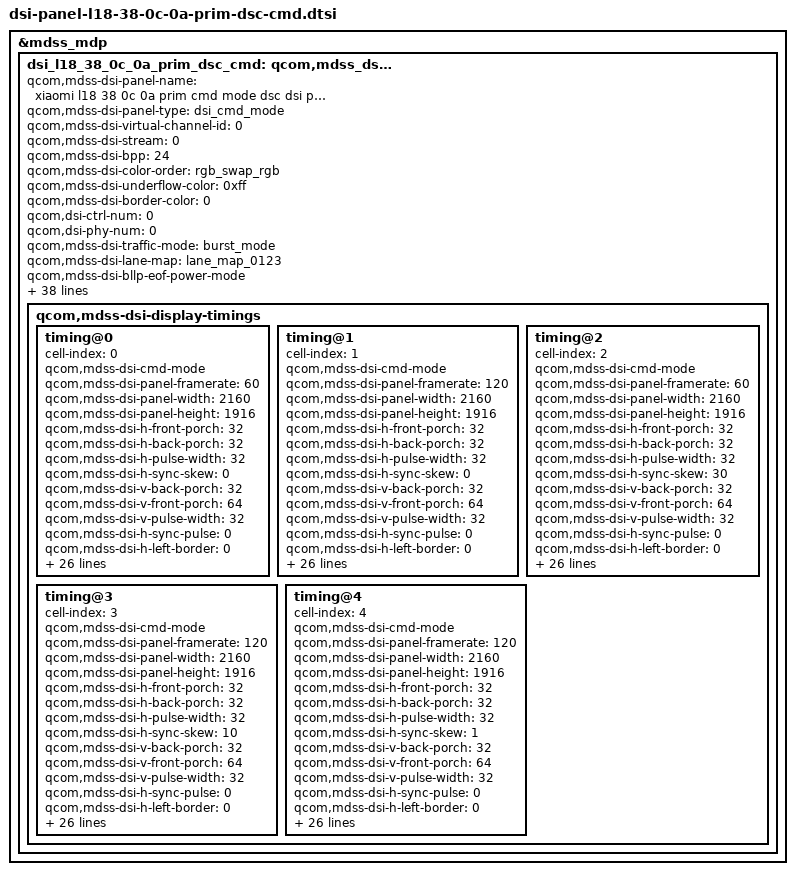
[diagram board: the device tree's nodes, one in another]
&mdss_mdp {
	dsi_l18_38_0c_0a_prim_dsc_cmd: qcom,mdss_dsi_l18_38_0c_0a_prim_dsc_cmd {
		qcom,mdss-dsi-panel-name = "xiaomi l18 38 0c 0a prim cmd mode dsc dsi panel";
		qcom,mdss-dsi-panel-type = "dsi_cmd_mode";
		qcom,mdss-dsi-virtual-channel-id = <0>;
		qcom,mdss-dsi-stream = <0>;
		qcom,mdss-dsi-bpp = <24>;
		qcom,mdss-dsi-color-order = "rgb_swap_rgb";
		qcom,mdss-dsi-underflow-color = <0xff>;
		qcom,mdss-dsi-border-color = <0>;
		qcom,dsi-ctrl-num = <0>;
		qcom,dsi-phy-num = <0>;

		qcom,mdss-dsi-traffic-mode = "burst_mode";
		qcom,mdss-dsi-lane-map = "lane_map_0123";
		qcom,mdss-dsi-bllp-eof-power-mode;
		qcom,mdss-dsi-bllp-power-mode;
		qcom,mdss-dsi-lane-0-state;
		qcom,mdss-dsi-lane-1-state;
		qcom,mdss-dsi-lane-2-state;
		qcom,mdss-dsi-lane-3-state;
		qcom,mdss-dsi-dma-trigger = "trigger_sw";
		qcom,mdss-dsi-mdp-trigger = "none";
		qcom,mdss-dsi-reset-sequence = <0 1>, <1 10>;
		qcom,mdss-pan-physical-width-dimension = <1350>;
		qcom,mdss-pan-physical-height-dimension = <1521>;
		qcom,mdss-dsi-te-pin-select = <1>;
		qcom,mdss-dsi-wr-mem-start = <0x2c>;
		qcom,mdss-dsi-wr-mem-continue = <0x3c>;
		qcom,mdss-dsi-te-dcs-command = <1>;
		qcom,mdss-dsi-te-check-enable;
		qcom,mdss-dsi-te-using-te-pin;
		qcom,mdss-dsi-tx-eot-append;
		qcom,mdss-dsi-lp11-init;

		qcom,mdss-dsi-panel-mode-switch;

		qcom,mdss-dsi-bl-inverted-dbv;
		qcom,bl-update-flag = "delay_until_first_frame";

		qcom,mdss-dsi-dma-schedule-line = <1>;
		qcom,mdss-dsi-dma-schedule-window = <10>;

		qcom,mdss-dsi-panel-hdr-enabled;
		qcom,mdss-dsi-panel-hdr-color-primaries = <14500 15500 32000
			17000 15500 30000 8000 3000>;
		qcom,mdss-dsi-panel-peak-brightness = <4200000>;
		qcom,mdss-dsi-panel-blackness-level = <3230>;

		qcom,mdss-dsi-display-timings {
			/* 60HZ */
			timing@0{
				#include "dsi-panel-l18-38-0c-0a-prim-dsc-cmd-common.dtsi"
				cell-index = <0>;
				qcom,mdss-dsi-cmd-mode;
				qcom,mdss-dsi-panel-framerate = <60>;
				qcom,mdss-dsi-panel-width = <2160>;
				qcom,mdss-dsi-panel-height = <1916>;
				qcom,mdss-dsi-h-front-porch = <32>;
				qcom,mdss-dsi-h-back-porch = <32>;
				qcom,mdss-dsi-h-pulse-width = <32>;
				qcom,mdss-dsi-h-sync-skew = <0>;
				qcom,mdss-dsi-v-back-porch = <32>;
				qcom,mdss-dsi-v-front-porch = <64>;
				qcom,mdss-dsi-v-pulse-width = <32>;
				qcom,mdss-dsi-h-sync-pulse = <0>;
				qcom,mdss-dsi-h-left-border = <0>;
				qcom,mdss-dsi-h-right-border = <0>;
				qcom,mdss-dsi-v-top-border = <0>;
				qcom,mdss-dsi-v-bottom-border = <0>;
				qcom,mdss-dsi-panel-clockrate = <1200000000>;
				qcom,mdss-dsi-panel-jitter = <0x5 0x1>;
				qcom,mdss-mdp-transfer-time-us = <7300>;
				qcom,mdss-dsi-on-command = [
					/* DSC Setting */
					39 00 00 00 00 00 5A 9E 11 00 00 89 30
					80 07 7C 08 70 01 DF 04 38 04 38 02
					00 03 1C 00 20 3D F1 00 0F 00 0C 00
					34 00 1C 18 00 10 F0 03 0C 20 00 06
					0B 0B 33 0E 1C 2A 38 46 54 62 69 70
					77 79 7B 7D 7E 01 02 01 00 09 40 09
					BE 19 FC 19 FA 19 F8 1A 38 1A 78 1A
					B6 2A F6 2B 34 2B 74 3B 74 6B F4 00
					/* Compression Enable */
					15 00 00 00 00 00 02 9D 01
					/* Sleep Out */
					05 00 00 00 78 00 02 11 00
					/* Common Setting */
					/* TE(Vsync) On */
					15 00 00 00 00 00 02 35 00
					/* CASET/PASET Setting 2160*1916 */
					39 00 00 40 00 00 05 2A 00 00 08 6F
					39 00 00 00 00 00 05 2B 00 00 07 7B
					/* TSP SYNC ENABLE */
					39 00 00 40 00 00 03 F0 5A 5A
					39 00 00 40 00 00 03 B0 09 B9
					39 00 00 40 00 00 04 B9 11 00 03
					39 00 00 00 00 00 03 F0 A5 A5
					/* Frequency Select 60.5Hz */
					39 00 00 40 00 00 03 F0 5A 5A
					39 00 00 40 00 00 03 60 08 00
					39 00 00 40 00 00 03 B0 03 F2
					15 00 00 40 00 00 02 F2 70
					15 00 00 40 00 00 02 B9 11
					15 00 00 40 00 00 02 F7 0F
					39 00 00 00 00 00 03 F0 A5 A5
					/* HOP Mode 60.5HZ */
					39 00 00 40 00 00 03 F0 5A 5A
					39 00 00 40 00 00 08 BD 01 00 00 80 00 01 C0
					39 00 00 40 00 00 03 60 08 01
					15 00 00 40 00 00 02 F7 0F
					39 00 00 00 00 00 03 F0 A5 A5
					/* Dimming Setting*/
					39 00 00 40 00 00 03 F0 5A 5A
					39 00 00 40 00 00 03 B0 02 B5
					39 00 00 40 00 00 02 B5 0F
					39 00 00 40 00 00 02 53 28
					39 00 00 40 00 00 03 51 00 00
					39 00 00 40 00 00 02 F7 0F
					39 00 00 00 00 00 03 F0 A5 A5
					/* Signal DC value setting after sleep out */
					39 00 00 40 00 00 03 F0 5A 5A
					39 00 00 40 00 00 03 B0 0A CB
					15 00 00 40 00 00 02 CB 0F
					39 00 00 40 00 00 03 B0 9D 64
					15 00 00 40 00 00 02 64 09
					15 00 00 40 00 00 02 F7 0F
					39 00 00 00 00 00 03 F0 A5 A5
					/* 2D SPR CTRL*/
					39 00 00 40 00 00 03 F0 5A 5A
					39 00 00 40 00 00 03 B0 64 B1
					39 00 00 40 00 00 02 B1 B8
					39 00 00 40 00 00 08 64 00 08 D8 D8 FF FF 40
					39 00 00 00 00 00 03 F0 A5 A5
					/* ERR Flag Setting ,ESD En*/
					39 00 00 40 00 00 03 F0 5A 5A
					39 00 00 40 00 00 03 B0 2A F4
					39 00 00 40 00 00 02 F4 3F
					39 00 00 40 00 00 04 ED 43 49 62
					39 00 00 00 00 00 03 F0 A5 A5
					/*flat dimming*/
					39 00 00 40 00 00 03 F0 5A 5A
					39 00 00 40 00 00 03 B0 C5 93
					15 00 00 40 00 00 02 93 87
					39 00 00 00 00 00 03 F0 A5 A5
					/*round corner improve*/
					39 00 00 40 00 00 03 F0 5A 5A
					39 00 00 40 00 00 03 B0 29 F2
					15 00 00 40 00 00 02 F2 04
					39 00 00 00 00 00 03 F0 A5 A5
					/* Display On */
					05 00 00 00 00 00 02 29 00
				];
				qcom,mdss-dsi-on-command-state = "dsi_lp_mode";
				qcom,mdss-dsi-off-command = [
					05 00 00 00 00 00 02 28 00
					05 00 00 00 0A 00 02 10 00
					39 00 00 40 00 00 03 F0 5A 5A
					39 00 00 40 00 00 03 B0 0A CB
					15 00 00 40 00 00 02 CB 4F
					15 00 00 40 00 00 02 F7 0F
					39 00 00 00 78 00 03 F0 A5 A5
				];
				qcom,mdss-dsi-off-command-state = "dsi_lp_mode";

				qcom,mdss-dsi-timing-switch-command = [
					39 00 00 40 00 00 03 F0 5A 5A
					39 00 00 40 00 00 03 60 08 00
					39 00 00 40 00 00 03 B0 03 F2
					/* Fix Te On */
					39 00 00 40 00 00 02 F2 70
					39 00 00 40 00 00 02 B9 11
					/* HOP Mode */
					39 00 00 40 00 00 08 BD 01 00 00 80 00 01 C0
					/* Frequency Select 60.5Hz */
					39 00 00 40 00 00 03 60 08 01
					39 00 00 00 00 00 02 F7 0F
				];
				qcom,mdss-dsi-timing-switch-command-state = "dsi_hs_mode";

				qcom,mdss-dsi-nolp-command = [
					39 00 00 40 00 00 03 F0 5A 5A
					39 00 00 40 00 00 03 B0 02 B5
					15 00 00 40 00 00 02 B5 0F
					15 00 00 40 00 00 02 53 20
					15 00 00 40 00 00 02 F7 0F
					/* Frequency Select 60.5Hz */
					39 00 00 40 00 00 03 60 08 00
					39 00 00 40 00 00 03 B0 03 F2
					15 00 00 40 00 00 02 F2 70
					15 00 00 40 00 00 02 B9 11
					15 00 00 40 00 00 02 F7 0F
					39 00 00 00 00 00 03 F0 A5 A5
				];
				qcom,mdss-dsi-nolp-command-state = "dsi_lp_mode";

				qcom,compression-mode = "dsc";
				qcom,mdss-dsc-slice-height = <479>;
				qcom,mdss-dsc-slice-width = <1080>;
				qcom,mdss-dsc-slice-per-pkt = <2>;
				qcom,mdss-dsc-bit-per-component = <8>;
				qcom,mdss-dsc-bit-per-pixel = <8>;
				qcom,mdss-dsc-block-prediction-enable;
			};

			/* 120HZ */
			timing@1{
				#include "dsi-panel-l18-38-0c-0a-prim-dsc-cmd-common.dtsi"
				cell-index = <1>;
				qcom,mdss-dsi-cmd-mode;
				qcom,mdss-dsi-panel-framerate = <120>;
				qcom,mdss-dsi-panel-width = <2160>;
				qcom,mdss-dsi-panel-height = <1916>;
				qcom,mdss-dsi-h-front-porch = <32>;
				qcom,mdss-dsi-h-back-porch = <32>;
				qcom,mdss-dsi-h-pulse-width = <32>;
				qcom,mdss-dsi-h-sync-skew = <0>;
				qcom,mdss-dsi-v-back-porch = <32>;
				qcom,mdss-dsi-v-front-porch = <64>;
				qcom,mdss-dsi-v-pulse-width = <32>;
				qcom,mdss-dsi-h-sync-pulse = <0>;
				qcom,mdss-dsi-h-left-border = <0>;
				qcom,mdss-dsi-h-right-border = <0>;
				qcom,mdss-dsi-v-top-border = <0>;
				qcom,mdss-dsi-v-bottom-border = <0>;
				qcom,mdss-dsi-panel-clockrate = <1200000000>;
				qcom,mdss-dsi-panel-jitter = <0x5 0x1>;
				qcom,mdss-mdp-transfer-time-us = <7300>;

				qcom,mdss-dsi-on-command = [
					/* DSC Setting */
					39 00 00 00 00 00 5A 9E 11 00 00 89 30
					80 07 7C 08 70 01 DF 04 38 04 38 02
					00 03 1C 00 20 3D F1 00 0F 00 0C 00
					34 00 1C 18 00 10 F0 03 0C 20 00 06
					0B 0B 33 0E 1C 2A 38 46 54 62 69 70
					77 79 7B 7D 7E 01 02 01 00 09 40 09
					BE 19 FC 19 FA 19 F8 1A 38 1A 78 1A
					B6 2A F6 2B 34 2B 74 3B 74 6B F4 00
					/* Compression Enable */
					15 00 00 00 00 00 02 9D 01
					/* Sleep Out */
					05 00 00 00 78 00 02 11 00
					/* Common Setting */
					/* TE(Vsync) On */
					15 00 00 00 00 00 02 35 00
					/* CASET/PASET Setting 2160*1916 */
					39 00 00 40 00 00 05 2A 00 00 08 6F
					39 00 00 00 00 00 05 2B 00 00 07 7B
					/* TSP SYNC ENABLE */
					39 00 00 40 00 00 03 F0 5A 5A
					39 00 00 40 00 00 03 B0 09 B9
					39 00 00 40 00 00 04 B9 11 00 03
					39 00 00 00 00 00 03 F0 A5 A5
					/* Frequency Select 121Hz */
					39 00 00 40 00 00 03 F0 5A 5A
					39 00 00 40 00 00 03 60 08 00
					39 00 00 40 00 00 03 B0 03 F2
					15 00 00 40 00 00 02 F2 70
					15 00 00 40 00 00 02 B9 02
					15 00 00 40 00 00 02 F7 0F
					39 00 00 00 00 00 03 F0 A5 A5
					/* HOP Mode 121HZ */
					39 00 00 40 00 00 03 F0 5A 5A
					39 00 00 40 00 00 08 BD 01 00 00 80 00 01 C0
					39 00 00 40 00 00 03 60 08 00
					15 00 00 40 00 00 02 F7 0F
					39 00 00 00 00 00 03 F0 A5 A5
					/* Dimming Setting */
					39 00 00 40 00 00 03 F0 5A 5A
					39 00 00 40 00 00 03 B0 02 B5
					39 00 00 40 00 00 02 B5 0F
					39 00 00 40 00 00 02 53 28
					39 00 00 40 00 00 03 51 00 00
					39 00 00 40 00 00 02 F7 0F
					39 00 00 00 00 00 03 F0 A5 A5
					/* Signal DC value setting after sleep out */
					39 00 00 40 00 00 03 F0 5A 5A
					39 00 00 40 00 00 03 B0 0A CB
					15 00 00 40 00 00 02 CB 0F
					39 00 00 40 00 00 03 B0 9D 64
					15 00 00 40 00 00 02 64 09
					15 00 00 40 00 00 02 F7 0F
					39 00 00 00 00 00 03 F0 A5 A5
					/* 2D SPR CTRL*/
					39 00 00 40 00 00 03 F0 5A 5A
					39 00 00 40 00 00 03 B0 64 B1
					39 00 00 40 00 00 02 B1 B8
					39 00 00 40 00 00 08 64 00 08 D8 D8 FF FF 40
					39 00 00 00 00 00 03 F0 A5 A5
					/* ERR Flag Setting ,ESD En*/
					39 00 00 40 00 00 03 F0 5A 5A
					39 00 00 40 00 00 03 B0 2A F4
					39 00 00 40 00 00 02 F4 3F
					39 00 00 40 00 00 04 ED 43 49 62
					39 00 00 00 00 00 03 F0 A5 A5
					/*flat dimming*/
					39 00 00 40 00 00 03 F0 5A 5A
					39 00 00 40 00 00 03 B0 C5 93
					15 00 00 40 00 00 02 93 87
					39 00 00 00 00 00 03 F0 A5 A5
					/*round corner improve*/
					39 00 00 40 00 00 03 F0 5A 5A
					39 00 00 40 00 00 03 B0 29 F2
					15 00 00 40 00 00 02 F2 04
					39 00 00 00 00 00 03 F0 A5 A5
					/* Display On */
					05 00 00 00 00 00 02 29 00
				];
				qcom,mdss-dsi-on-command-state = "dsi_lp_mode";
				qcom,mdss-dsi-off-command = [
					05 00 00 00 00 00 02 28 00
					05 00 00 00 0A 00 02 10 00
					39 00 00 40 00 00 03 F0 5A 5A
					39 00 00 40 00 00 03 B0 0A CB
					15 00 00 40 00 00 02 CB 4F
					15 00 00 40 00 00 02 F7 0F
					39 00 00 00 78 00 03 F0 A5 A5
				];
				qcom,mdss-dsi-off-command-state = "dsi_lp_mode";

				qcom,mdss-dsi-timing-switch-command = [
					39 00 00 40 00 00 03 F0 5A 5A
					39 00 00 40 00 00 03 60 08 00
					39 00 00 40 00 00 03 B0 03 F2
					/* Fix Te On */
					39 00 00 40 00 00 02 F2 70
					39 00 00 40 00 00 02 B9 02
					/* HOP Mode */
					39 00 00 40 00 00 08 BD 01 00 00 80 00 01 C0
					/* 120HZ */
					39 00 00 40 00 00 03 60 08 00
					39 00 00 00 00 00 02 F7 0F
				];
				qcom,mdss-dsi-timing-switch-command-state = "dsi_hs_mode";

				qcom,mdss-dsi-nolp-command = [
					39 00 00 40 00 00 03 F0 5A 5A
					39 00 00 40 00 00 03 B0 02 B5
					15 00 00 40 00 00 02 B5 0F
					15 00 00 40 00 00 02 53 20
					15 00 00 40 00 00 02 F7 0F
					/* Frequency Select 121Hz */
					39 00 00 40 00 00 03 60 08 00
					39 00 00 40 00 00 03 B0 03 F2
					15 00 00 40 00 00 02 F2 70
					15 00 00 40 00 00 02 B9 02
					15 00 00 40 00 00 02 F7 0F
					39 00 00 00 00 00 03 F0 A5 A5
				];
				qcom,mdss-dsi-nolp-command-state = "dsi_lp_mode";

				qcom,compression-mode = "dsc";
				qcom,mdss-dsc-slice-height = <479>;
				qcom,mdss-dsc-slice-width = <1080>;
				qcom,mdss-dsc-slice-per-pkt = <2>;
				qcom,mdss-dsc-bit-per-component = <8>;
				qcom,mdss-dsc-bit-per-pixel = <8>;
				qcom,mdss-dsc-block-prediction-enable;
			};

			/* 30HZ */
			timing@2{
				#include "dsi-panel-l18-38-0c-0a-prim-dsc-cmd-common.dtsi"
				cell-index = <2>;
				qcom,mdss-dsi-cmd-mode;
				qcom,mdss-dsi-panel-framerate = <60>;
				qcom,mdss-dsi-panel-width = <2160>;
				qcom,mdss-dsi-panel-height = <1916>;
				qcom,mdss-dsi-h-front-porch = <32>;
				qcom,mdss-dsi-h-back-porch = <32>;
				qcom,mdss-dsi-h-pulse-width = <32>;
				qcom,mdss-dsi-h-sync-skew = <30>;
				qcom,mdss-dsi-v-back-porch = <32>;
				qcom,mdss-dsi-v-front-porch = <64>;
				qcom,mdss-dsi-v-pulse-width = <32>;
				qcom,mdss-dsi-h-sync-pulse = <0>;
				qcom,mdss-dsi-h-left-border = <0>;
				qcom,mdss-dsi-h-right-border = <0>;
				qcom,mdss-dsi-v-top-border = <0>;
				qcom,mdss-dsi-v-bottom-border = <0>;
				qcom,mdss-dsi-panel-clockrate = <1200000000>;
				qcom,mdss-dsi-panel-jitter = <0x5 0x1>;
				qcom,mdss-mdp-transfer-time-us = <7300>;

				qcom,mdss-dsi-on-command = [
					/* DSC Setting */
					0A 00 00 00 00 00 5A 9E 11 00 00 89 30
						80 07 7C 08 70 01 DF 04 38 04 38 02
						00 03 1C 00 20 3D F1 00 0F 00 0C 00
						34 00 1C 18 00 10 F0 03 0C 20 00 06
						0B 0B 33 0E 1C 2A 38 46 54 62 69 70
						77 79 7B 7D 7E 01 02 01 00 09 40 09
						BE 19 FC 19 FA 19 F8 1A 38 1A 78 1A
						B6 2A F6 2B 34 2B 74 3B 74 6B F4 00
					/* Compression Enable */
					07 00 00 00 00 00 02 9D 01
					/* Sleep Out */
					05 00 00 00 78 00 02 11 00
					/* Common Setting */
					/* TE(Vsync) On */
					15 00 00 00 00 00 02 35 00
					/* CASET/PASET Setting 2160*1916 */
					39 00 00 40 00 00 05 2A 00 00 08 6F
					39 00 00 00 00 00 05 2B 00 00 07 7B
					/* TSP SYNC ENABLE */
					39 00 00 40 00 00 03 F0 5A 5A
					15 00 00 40 00 00 02 B9 00
					39 00 00 40 00 00 03 B0 09 B9
					39 00 00 40 00 00 04 B9 11 00 03
					39 00 00 00 00 00 03 F0 A5 A5
					/* Frequency Select 30.25Hz */
					39 00 00 40 00 00 03 F0 5A 5A
					39 00 00 40 00 00 03 60 08 00
					39 00 00 40 00 00 03 B0 03 F2
					15 00 00 40 00 00 02 F2 70 /* 0x70 : Fixed TE on; 0x74 : Fixed TE off */
					15 00 00 40 00 00 02 B9 11 /* set TE fix 60hz */
					15 00 00 40 00 00 02 F7 0F
					39 00 00 00 00 00 03 F0 A5 A5
					/* HOP Mode 30.25HZ */
					39 00 00 40 00 00 03 F0 5A 5A
					39 00 00 40 00 00 08 BD 01 00 00 80 00 01 C0
					39 00 00 40 00 00 03 60 08 03
					15 00 00 40 00 00 02 F7 0F
					39 00 00 00 00 00 03 F0 A5 A5
					/* Dimming Setting */
					39 00 00 40 00 00 03 F0 5A 5A
					39 00 00 40 00 00 03 B0 02 B5
					39 00 00 40 00 00 02 B5 0F
					39 00 00 40 00 00 02 53 28
					39 00 00 40 00 00 03 51 00 00
					39 00 00 40 00 00 02 F7 0F
					39 00 00 00 00 00 03 F0 A5 A5
					/* Signal DC value setting after sleep out */
					39 00 00 40 00 00 03 F0 5A 5A
					39 00 00 40 00 00 03 B0 0A CB
					15 00 00 40 00 00 02 CB 0F
					39 00 00 40 00 00 03 B0 9D 64
					15 00 00 40 00 00 02 64 09
					15 00 00 40 00 00 02 F7 0F
					39 00 00 00 00 00 03 F0 A5 A5
					/* 2D SPR CTRL*/
					39 00 00 40 00 00 03 F0 5A 5A
					39 00 00 40 00 00 03 B0 64 B1
					39 00 00 40 00 00 02 B1 B8
					39 00 00 40 00 00 08 64 00 08 D8 D8 FF FF 40
					39 00 00 00 00 00 03 F0 A5 A5
					/* ERR Flag Setting ,ESD En*/
					39 00 00 40 00 00 03 F0 5A 5A
					39 00 00 40 00 00 03 B0 2A F4
					39 00 00 40 00 00 02 F4 3F
					39 00 00 40 00 00 04 ED 43 49 62
					39 00 00 00 00 00 03 F0 A5 A5
					/*flat dimming*/
					39 00 00 40 00 00 03 F0 5A 5A
					39 00 00 40 00 00 03 B0 C5 93
					15 00 00 40 00 00 02 93 87
					39 00 00 00 00 00 03 F0 A5 A5
					/*round corner improve*/
					39 00 00 40 00 00 03 F0 5A 5A
					39 00 00 40 00 00 03 B0 29 F2
					15 00 00 40 00 00 02 F2 04
					39 00 00 00 00 00 03 F0 A5 A5
					/* Display On */
					05 00 00 00 00 00 02 29 00
				];
				qcom,mdss-dsi-on-command-state = "dsi_lp_mode";
				qcom,mdss-dsi-off-command = [
					05 00 00 00 00 00 02 28 00
					05 00 00 00 0A 00 02 10 00
					39 00 00 40 00 00 03 F0 5A 5A
					39 00 00 40 00 00 03 B0 0A CB
					15 00 00 40 00 00 02 CB 4F
					15 00 00 40 00 00 02 F7 0F
					39 00 00 00 78 00 03 F0 A5 A5
				];
				qcom,mdss-dsi-off-command-state = "dsi_lp_mode";

				qcom,mdss-dsi-timing-switch-command = [
					39 00 00 40 00 00 03 F0 5A 5A
					39 00 00 40 00 00 03 60 08 00
					39 00 00 40 00 00 02 B9 11 /* set TE fix 60hz */
					39 00 00 40 00 00 03 B0 03 F2
					/* Fix Te On */
					39 00 00 40 00 00 02 F2 70  /* 0x70 : Fixed TE on; 0x74 : Fixed TE off */
					/* HOP Mode  */
					39 00 00 40 00 00 08 BD 01 00 00 80 00 01 C0
					/* 30.25 HZ */
					39 00 00 40 00 00 03 60 08 03
					39 00 00 00 00 00 02 F7 0F
				];
				qcom,mdss-dsi-timing-switch-command-state = "dsi_hs_mode";

				qcom,mdss-dsi-nolp-command = [
					39 00 00 40 00 00 03 F0 5A 5A
					39 00 00 40 00 00 03 B0 02 B5
					15 00 00 40 00 00 02 B5 0F
					15 00 00 40 00 00 02 53 20
					15 00 00 40 00 00 02 F7 0F
					/* Frequency Select 60.5Hz */
					39 00 00 40 00 00 03 60 08 00
					39 00 00 40 00 00 03 B0 03 F2
					15 00 00 40 00 00 02 F2 70
					15 00 00 40 00 00 02 B9 11
					15 00 00 40 00 00 02 F7 0F
					39 00 00 00 00 00 03 F0 A5 A5
				];
				qcom,mdss-dsi-nolp-command-state = "dsi_lp_mode";

				qcom,compression-mode = "dsc";
				qcom,mdss-dsc-slice-height = <479>;
				qcom,mdss-dsc-slice-width = <1080>;
				qcom,mdss-dsc-slice-per-pkt = <2>;
				qcom,mdss-dsc-bit-per-component = <8>;
				qcom,mdss-dsc-bit-per-pixel = <8>;
				qcom,mdss-dsc-block-prediction-enable;
			};

			/*10 HZ*/
			timing@3{
				#include "dsi-panel-l18-38-0c-0a-prim-dsc-cmd-common.dtsi"
				cell-index = <3>;
				qcom,mdss-dsi-cmd-mode;
				qcom,mdss-dsi-panel-framerate = <120>;
				qcom,mdss-dsi-panel-width = <2160>;
				qcom,mdss-dsi-panel-height = <1916>;
				qcom,mdss-dsi-h-front-porch = <32>;
				qcom,mdss-dsi-h-back-porch = <32>;
				qcom,mdss-dsi-h-pulse-width = <32>;
				qcom,mdss-dsi-h-sync-skew = <10>;
				qcom,mdss-dsi-v-back-porch = <32>;
				qcom,mdss-dsi-v-front-porch = <64>;
				qcom,mdss-dsi-v-pulse-width = <32>;
				qcom,mdss-dsi-h-sync-pulse = <0>;
				qcom,mdss-dsi-h-left-border = <0>;
				qcom,mdss-dsi-h-right-border = <0>;
				qcom,mdss-dsi-v-top-border = <0>;
				qcom,mdss-dsi-v-bottom-border = <0>;
				qcom,mdss-dsi-panel-clockrate = <1200000000>;
				qcom,mdss-dsi-panel-jitter = <0x5 0x1>;
				qcom,mdss-mdp-transfer-time-us = <7300>;

				qcom,mdss-dsi-on-command = [
					/* DSC Setting */
					39 00 00 00 00 00 5A 9E 11 00 00 89 30
					80 07 7C 08 70 01 DF 04 38 04 38 02
					00 03 1C 00 20 3D F1 00 0F 00 0C 00
					34 00 1C 18 00 10 F0 03 0C 20 00 06
					0B 0B 33 0E 1C 2A 38 46 54 62 69 70
					77 79 7B 7D 7E 01 02 01 00 09 40 09
					BE 19 FC 19 FA 19 F8 1A 38 1A 78 1A
					B6 2A F6 2B 34 2B 74 3B 74 6B F4 00
					/* Compression Enable */
					15 00 00 00 00 00 02 9D 01
					/* Sleep Out */
					05 00 00 00 78 00 02 11 00
					/* Common Setting */
					/* TE(Vsync) On */
					15 00 00 00 00 00 02 35 00
					/* CASET/PASET Setting 2160*1916 */
					39 00 00 40 00 00 05 2A 00 00 08 6F
					39 00 00 00 00 00 05 2B 00 00 07 7B
					/* TSP SYNC ENABLE */
					39 00 00 40 00 00 03 F0 5A 5A
					15 00 00 40 00 00 02 B9 02
					39 00 00 40 00 00 03 B0 09 B9
					39 00 00 40 00 00 04 B9 11 00 03
					39 00 00 00 00 00 03 F0 A5 A5
					/* Frequency Select 10Hz */
					39 00 00 40 00 00 03 F0 5A 5A
					39 00 00 40 00 00 03 60 08 0B
					39 00 00 40 00 00 03 B0 03 F2
					15 00 00 40 00 00 02 F2 70
					15 00 00 40 00 00 02 F7 0F
					39 00 00 00 00 00 03 F0 A5 A5
					/* HOP Mode 10HZ */
					39 00 00 40 00 00 03 F0 5A 5A
					39 00 00 40 00 00 18 BD 01 00 00 80 00 01 40 00 01 70 00 00 00 0B 00 00 00 00 00 00 02 00 14
					15 00 00 40 00 00 02 F7 0F
					39 00 00 00 00 00 03 F0 A5 A5
					/* Dimming Setting */
					39 00 00 40 00 00 03 F0 5A 5A
					39 00 00 40 00 00 03 B0 02 B5
					39 00 00 40 00 00 02 B5 0F
					39 00 00 40 00 00 02 53 28
					39 00 00 40 00 00 03 51 00 00
					39 00 00 40 00 00 02 F7 0F
					39 00 00 00 00 00 03 F0 A5 A5
					/* Signal DC value setting after sleep out */
					39 00 00 40 00 00 03 F0 5A 5A
					39 00 00 40 00 00 03 B0 0A CB
					15 00 00 40 00 00 02 CB 0F
					39 00 00 40 00 00 03 B0 9D 64
					15 00 00 40 00 00 02 64 09
					15 00 00 40 00 00 02 F7 0F
					39 00 00 00 00 00 03 F0 A5 A5
					/* 2D SPR CTRL*/
					39 00 00 40 00 00 03 F0 5A 5A
					39 00 00 40 00 00 03 B0 64 B1
					39 00 00 40 00 00 02 B1 B8
					39 00 00 40 00 00 08 64 00 08 D8 D8 FF FF 40
					39 00 00 00 00 00 03 F0 A5 A5
					/* ERR Flag Setting ,ESD En*/
					39 00 00 40 00 00 03 F0 5A 5A
					39 00 00 40 00 00 03 B0 2A F4
					39 00 00 40 00 00 02 F4 3F
					39 00 00 40 00 00 04 ED 43 49 62
					39 00 00 00 00 00 03 F0 A5 A5
					/*flat dimming*/
					39 00 00 40 00 00 03 F0 5A 5A
					39 00 00 40 00 00 03 B0 C5 93
					15 00 00 40 00 00 02 93 87
					39 00 00 00 00 00 03 F0 A5 A5
					/*round corner improve*/
					39 00 00 40 00 00 03 F0 5A 5A
					39 00 00 40 00 00 03 B0 29 F2
					15 00 00 40 00 00 02 F2 04
					39 00 00 00 00 00 03 F0 A5 A5
					/* Display On */
					05 00 00 00 00 00 02 29 00
				];
				qcom,mdss-dsi-on-command-state = "dsi_lp_mode";
				qcom,mdss-dsi-off-command = [
					05 00 00 00 00 00 02 28 00
					05 00 00 00 0A 00 02 10 00
					39 00 00 40 00 00 03 F0 5A 5A
					39 00 00 40 00 00 03 B0 0A CB
					15 00 00 40 00 00 02 CB 4F
					15 00 00 40 00 00 02 F7 0F
					39 00 00 00 78 00 03 F0 A5 A5
				];
				qcom,mdss-dsi-off-command-state = "dsi_lp_mode";

				qcom,mdss-dsi-timing-switch-command = [
					39 00 00 40 00 00 03 F0 5A 5A
					39 00 00 40 00 00 03 60 08 00
					39 00 00 40 00 00 03 B0 03 F2
					/* Fix TE On */
					39 00 00 40 00 00 02 F2 70
					15 00 00 40 00 00 02 B9 02
					/* HOP auto mode 10hz */
					39 00 00 40 00 00 18 BD 01 00 00 80 00 01 40 00 01 70 00 00 00 0B  00 00 00 00 00 00 02 00 14
					39 00 00 00 00 00 02 F7 0F
				];
				qcom,mdss-dsi-timing-switch-command-state = "dsi_hs_mode";

				qcom,mdss-dsi-nolp-command = [
					39 00 00 40 00 00 03 F0 5A 5A
					39 00 00 40 00 00 03 B0 02 B5
					15 00 00 40 00 00 02 B5 0F
					15 00 00 40 00 00 02 53 20
					15 00 00 40 00 00 02 F7 0F
					/* Frequency Select 60.5Hz */
					39 00 00 40 00 00 03 60 08 00
					39 00 00 40 00 00 03 B0 03 F2
					15 00 00 40 00 00 02 F2 70
					15 00 00 40 00 00 02 B9 11
					15 00 00 40 00 00 02 F7 0F
					39 00 00 00 00 00 03 F0 A5 A5
				];
				qcom,mdss-dsi-nolp-command-state = "dsi_lp_mode";

				qcom,compression-mode = "dsc";
				qcom,mdss-dsc-slice-height = <479>;
				qcom,mdss-dsc-slice-width = <1080>;
				qcom,mdss-dsc-slice-per-pkt = <2>;
				qcom,mdss-dsc-bit-per-component = <8>;
				qcom,mdss-dsc-bit-per-pixel = <8>;
				qcom,mdss-dsc-block-prediction-enable;
			};

			/*1HZ*/
			timing@4{
				#include "dsi-panel-l18-38-0c-0a-prim-dsc-cmd-common.dtsi"
				cell-index = <4>;
				qcom,mdss-dsi-cmd-mode;
				qcom,mdss-dsi-panel-framerate = <120>;
				qcom,mdss-dsi-panel-width = <2160>;
				qcom,mdss-dsi-panel-height = <1916>;
				qcom,mdss-dsi-h-front-porch = <32>;
				qcom,mdss-dsi-h-back-porch = <32>;
				qcom,mdss-dsi-h-pulse-width = <32>;
				qcom,mdss-dsi-h-sync-skew = <1>;
				qcom,mdss-dsi-v-back-porch = <32>;
				qcom,mdss-dsi-v-front-porch = <64>;
				qcom,mdss-dsi-v-pulse-width = <32>;
				qcom,mdss-dsi-h-sync-pulse = <0>;
				qcom,mdss-dsi-h-left-border = <0>;
				qcom,mdss-dsi-h-right-border = <0>;
				qcom,mdss-dsi-v-top-border = <0>;
				qcom,mdss-dsi-v-bottom-border = <0>;
				qcom,mdss-dsi-panel-clockrate = <1200000000>;
				qcom,mdss-dsi-panel-jitter = <0x5 0x1>;
				qcom,mdss-mdp-transfer-time-us = <7300>;

				qcom,mdss-dsi-on-command = [
					/* DSC Setting */
					39 00 00 00 00 00 5A 9E 11 00 00 89 30
					80 07 7C 08 70 01 DF 04 38 04 38 02
					00 03 1C 00 20 3D F1 00 0F 00 0C 00
					34 00 1C 18 00 10 F0 03 0C 20 00 06
					0B 0B 33 0E 1C 2A 38 46 54 62 69 70
					77 79 7B 7D 7E 01 02 01 00 09 40 09
					BE 19 FC 19 FA 19 F8 1A 38 1A 78 1A
					B6 2A F6 2B 34 2B 74 3B 74 6B F4 00
					/* Compression Enable */
					15 00 00 00 00 00 02 9D 01
					/* Sleep Out */
					05 00 00 00 78 00 02 11 00
					/* Common Setting */
					/* TE(Vsync) On */
					15 00 00 00 00 00 02 35 00
					/* CASET/PASET Setting 2160*1916 */
					39 00 00 40 00 00 05 2A 00 00 08 6F
					39 00 00 00 00 00 05 2B 00 00 07 7B
					/* TSP SYNC ENABLE */
					39 00 00 40 00 00 03 F0 5A 5A
					15 00 00 40 00 00 02 B9 02
					39 00 00 40 00 00 03 B0 09 B9
					39 00 00 40 00 00 04 B9 11 00 03
					39 00 00 00 00 00 03 F0 A5 A5
					/* Frequency Select 1Hz */
					39 00 00 40 00 00 03 F0 5A 5A
					39 00 00 40 00 00 03 60 08 77
					39 00 00 40 00 00 03 B0 03 F2
					15 00 00 40 00 00 02 F2 70
					15 00 00 40 00 00 02 F7 0F
					39 00 00 00 00 00 03 F0 A5 A5
					/* HOP Mode 1HZ */
					39 00 00 40 00 00 03 F0 5A 5A
					39 00 00 40 00 00 18 BD 01 00 00 80 00 01 40 00 01 70 00 00 00 77 00 00 00 00 00 00 02 00 14
					15 00 00 40 00 00 02 F7 0F
					39 00 00 00 00 00 03 F0 A5 A5
					/* Dimming Setting */
					39 00 00 40 00 00 03 F0 5A 5A
					39 00 00 40 00 00 03 B0 02 B5
					39 00 00 40 00 00 02 B5 0F
					39 00 00 40 00 00 02 53 28
					39 00 00 40 00 00 03 51 00 00
					39 00 00 40 00 00 02 F7 0F
					39 00 00 00 00 00 03 F0 A5 A5
					/* Signal DC value setting after sleep out */
					39 00 00 40 00 00 03 F0 5A 5A
					39 00 00 40 00 00 03 B0 0A CB
					15 00 00 40 00 00 02 CB 0F
					39 00 00 40 00 00 03 B0 9D 64
					15 00 00 40 00 00 02 64 09
					15 00 00 40 00 00 02 F7 0F
					39 00 00 00 00 00 03 F0 A5 A5
					/* 2D SPR CTRL*/
					39 00 00 40 00 00 03 F0 5A 5A
					39 00 00 40 00 00 03 B0 64 B1
					39 00 00 40 00 00 02 B1 B8
					39 00 00 40 00 00 08 64 00 08 D8 D8 FF FF 40
					39 00 00 00 00 00 03 F0 A5 A5
					/* ERR Flag Setting ,ESD En*/
					39 00 00 40 00 00 03 F0 5A 5A
					39 00 00 40 00 00 03 B0 2A F4
					39 00 00 40 00 00 02 F4 3F
					39 00 00 40 00 00 04 ED 43 49 62
					39 00 00 00 00 00 03 F0 A5 A5
					/*flat dimming*/
					39 00 00 40 00 00 03 F0 5A 5A
					39 00 00 40 00 00 03 B0 C5 93
					15 00 00 40 00 00 02 93 87
					39 00 00 00 00 00 03 F0 A5 A5
					/*round corner improve*/
					39 00 00 40 00 00 03 F0 5A 5A
					39 00 00 40 00 00 03 B0 29 F2
					15 00 00 40 00 00 02 F2 04
					39 00 00 00 00 00 03 F0 A5 A5
					/* Display On */
					05 00 00 00 00 00 02 29 00
				];
				qcom,mdss-dsi-on-command-state = "dsi_lp_mode";
				qcom,mdss-dsi-off-command = [
					05 00 00 00 00 00 02 28 00
					05 00 00 00 0A 00 02 10 00
					39 00 00 40 00 00 03 F0 5A 5A
					39 00 00 40 00 00 03 B0 0A CB
					15 00 00 40 00 00 02 CB 4F
					15 00 00 40 00 00 02 F7 0F
					39 00 00 00 78 00 03 F0 A5 A5
				];
				qcom,mdss-dsi-off-command-state = "dsi_lp_mode";

				qcom,mdss-dsi-timing-switch-command = [
					39 00 00 40 00 00 03 F0 5A 5A
					39 00 00 40 00 00 03 60 08 00
					39 00 00 40 00 00 03 B0 03 F2
					/* Fix TE On */
					39 00 00 40 00 00 02 F2 70
					15 00 00 40 00 00 02 B9 02
					/* HOP auto mode 1hz */
					39 00 00 40 00 00 18 BD 01 00 00 80 00 01 40 00 01 70 00 00 00 77 00 00 00 00 00 00 02 00 14
					39 00 00 00 00 00 02 F7 0F
				];
				qcom,mdss-dsi-timing-switch-command-state = "dsi_hs_mode";

				qcom,mdss-dsi-nolp-command = [
					39 00 00 40 00 00 03 F0 5A 5A
					39 00 00 40 00 00 03 B0 02 B5
					15 00 00 40 00 00 02 B5 0F
					15 00 00 40 00 00 02 53 20
					15 00 00 40 00 00 02 F7 0F
					/* Frequency Select 60.5Hz */
					39 00 00 40 00 00 03 60 08 00
					39 00 00 40 00 00 03 B0 03 F2
					15 00 00 40 00 00 02 F2 70
					15 00 00 40 00 00 02 B9 11
					15 00 00 40 00 00 02 F7 0F
					39 00 00 00 00 00 03 F0 A5 A5
				];
				qcom,mdss-dsi-nolp-command-state = "dsi_lp_mode";

				qcom,compression-mode = "dsc";
				qcom,mdss-dsc-slice-height = <479>;
				qcom,mdss-dsc-slice-width = <1080>;
				qcom,mdss-dsc-slice-per-pkt = <2>;
				qcom,mdss-dsc-bit-per-component = <8>;
				qcom,mdss-dsc-bit-per-pixel = <8>;
				qcom,mdss-dsc-block-prediction-enable;
			};
		};
	};
};

&dsi_l18_38_0c_0a_prim_dsc_cmd {
	mi,panel-id = <0x004C3138 0x50380C00>;

	mi,panel-on-dimming-delay = <120>;
	mi,max-brightness-clone = <16383>;
	mi,doze-hbm-dbv-level = <196>;
	mi,doze-lbm-dbv-level = <22>;

	/* IRQF_ONESHOT | IRQF_TRIGGER_LOW */
	mi,esd-err-irq-gpio = <&tlmm 116 0x2008>;
	mi,mdss-dsi-panel-dc-threshold = <348>;
	mi,dc-feature-enabled;
	mi,thermal-dimming-flag;
	mi,dc-feature-type = "crc_skip_backlight";
};

